# YTM32B1ME0 register map
Vendor: YTMicro; File version: 1.6
CPU: CM33 r0p4, little endian, MPU, FPU, 2 interrupt priority bits
Registers are 32-bit, read-write, reset 0x0 unless marked. A register's access mark holds for its fields unless they carry their own. Offsets are from the block's base; [hi:lo] are bit positions; {n}, {i} and the like mark numbered series.

## PCTRLA — PORT Control
Base 0x40012000; register names take the prefix PCTRLA_
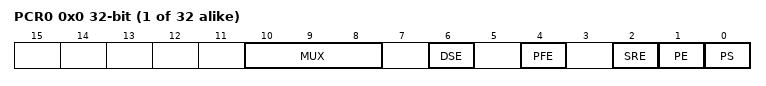
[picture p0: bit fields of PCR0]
{0x0+4i} PCR{i} (i=0..31) — Port control register
  [10:8] MUX — Not all pin muxing slots are implemented. Unimplemented pin muxing slots are reserved. Please refer to pinmux table for detailed peripheral functions. The corresponding pin is configured in the following pin muxing slot as follows:
    0=Alternative 0, Analog function, digital function is disabled; 1=Alternative 1, GPIO function; {v}=Alternative {v} (v=2..7)
  [6] DSE — Drive strength configuration for digital pin muxing.
    0=Low drive strength, if the pin is configured as a digital output; 1=High drive strength, if the pin is configured as a digital output
  [4] PFE — Passive filter configuration for digital pin muxing.
    0=Passive input filter is disabled; 1=Passive input filter is enabled, if the pin is configured as a digital input
  [2] SRE — Slew rate configuration for digital pin muxing.
    0=Fast slew rate, if the pin is configured as a digital output; 1=Slow slew rate, if the pin is configured as a digital output
  [1] PE — Pull configuration for digital pin muxing.
    0=Internal pullup or pulldown resistor is not enabled; 1=Internal pullup or pulldown resistor is enabled
  [0] PS — Pull configuration for digital pin muxing.
    0=Internal pulldown resistor is enabled, if PE field is set; 1=Internal pullup resistor is enabled, if PE field is set

## PCTRLB — PORT Control
Base 0x40013000; register names take the prefix PCTRLB_
Registers as PCTRLA.

## PCTRLC — PORT Control
Base 0x40014000; register names take the prefix PCTRLC_
Registers as PCTRLA.

## PCTRLD — PORT Control
Base 0x40015000; register names take the prefix PCTRLD_
Registers as PCTRLA.

## PCTRLE — PORT Control
Base 0x40016000; register names take the prefix PCTRLE_
Registers as PCTRLA.

## TMU — Trigger Multiplexer Module
Base 0x40048000; register names take the prefix TMU_
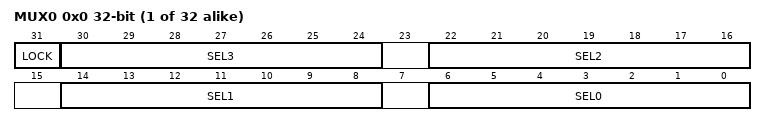
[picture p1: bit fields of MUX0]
{0x0+4i} MUX{i} (i=0..31)
  [31] LOCK — Lock the MUX select for peripheral trigger input
  [8n+6:8n] SEL{n} (n=0..3) — This read/write bit field is used to configure the MUX select for peripheral trigger input.

## IPC — IP Control
Base 0x4007D000; register names take the prefix IPC_
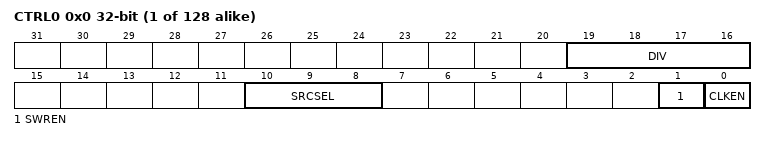
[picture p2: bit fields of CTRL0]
{0x0+4i} CTRL{i} (i=0..127)
  [19:16] DIV — The divide value = register value + 1
    0=No devided; {v}=Divided by {v+1} (v=1..15)
  [10:8] SRCSEL
    0=no clock; 1=select FIRC; 2=select SIRC; 3=select FXOSC; 4=select SXOSC; 5=select PLL
  [1] SWREN — Not all modules support, please see \hyperref[ip-clock-control-tab]{Software Reset column} of above table for more information.
    0=Software reset is de-asserted; 1=Software reset is asserted
  [0] CLKEN — Not all modules support, please see \hyperref[ip-clock-control-tab]{Bus Clock Enable column} of above table for more information.
    0=IP clock is disabled; 1=IP clock is enabled

## RCU — Reset Contru Unit of Microcontroller
Base 0x4007F000; register names take the prefix RCU_
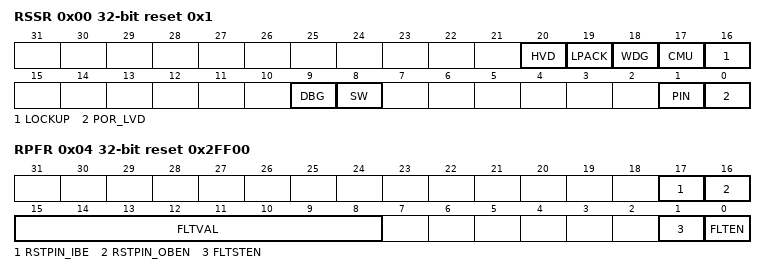
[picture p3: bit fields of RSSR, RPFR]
0x00 RSSR reset 0x1 — This register includes read-only status flags to indicate the source of the most recent reset. Multiple flags will be set if multiple reset events occur at the same time.
  [20] HVD — System reset caused by Clock Monitor HVD.
    0=System reset not caused by HVD; 1=System reset caused by HVD
  [19] LPACK — System reset caused by low power mode entry acknowledge timeout, indicates that a system reset has been caused during an attempt to enter the low power mode (Deepsleep/Standby/Powerdown Mode), while one or more peripherals fail to acknowledge on time.
    0=System reset not caused by Deepsleep/Standby/Powerdown mode entry timeout; 1=System reset caused by Deepsleep/Standby/Powerdown mode entry timeout
  [18] WDG — System reset caused by Clock Monitor Watchdog.
    0=System reset not caused by WDG; 1=System reset caused by WDG
  [17] CMU — System reset caused by Clock Monitor if CMUn_RE is set.
    0=System reset not caused by CMU; 1=System reset caused by CMU
  [16] LOCKUP — System reset caused by ARM Core Lockup.
    0=System reset not caused by Lockup; 1=System reset caused by Lockup
  [9] DBG — System reset caused by Debug.
    0=System reset not caused by debug; 1=System reset caused by debug
  [8] SW — System reset caused by software to set SYSRESETREQ of ARM Core.
    0=System reset not caused by SW; 1=System reset caused by SW
  [1] PIN — System reset caused by RESET_b pin.
    0=System reset not caused by PIN; 1=System reset caused by PIN
  [0] POR_LVD — System reset caused by POR/LVD.
    0=System reset not caused by POR/LVD; 1=System reset caused by POR/LVD
0x04 RPFR reset 0x2FF00 — This register controls the reset pin filter functions.
  [17] RSTPIN_IBE — Enable bit of Reset pin input
    0=reset pin ind is disabled; 1=reset pin ind is enabled
  [16] RSTPIN_OBEN — Enable bit of Reset pin output
    0=Not output low on reset pin when chip reset occurs; 1=Output low on reset pin when chip reset occurs
  [15:8] FLTVAL — FLTVAL control the filter counter value of SIRC clock cycles
    0=Filter counter value is 0x00; 255=Filter counter value is 0xFF
  [1] FLTSTEN — Enable bit of Reset pin filter in Deepsleep and Standby mode, this bit should be set if filter need to be used in Deepsleep and Standby mode. This bit has no effect of reset pin filter in active mode.
    0=Disable reset pin filter in Deepsleep and Standby mode; 1=Enable reset pin filter in Deepsleep and Standby mode if FLTEN is set
  [0] FLTEN — Enable bit of Reset pin filter, this bit should be set if filter need to be used.
    0=Disable reset pin filter; 1=Enable reset pin filter
